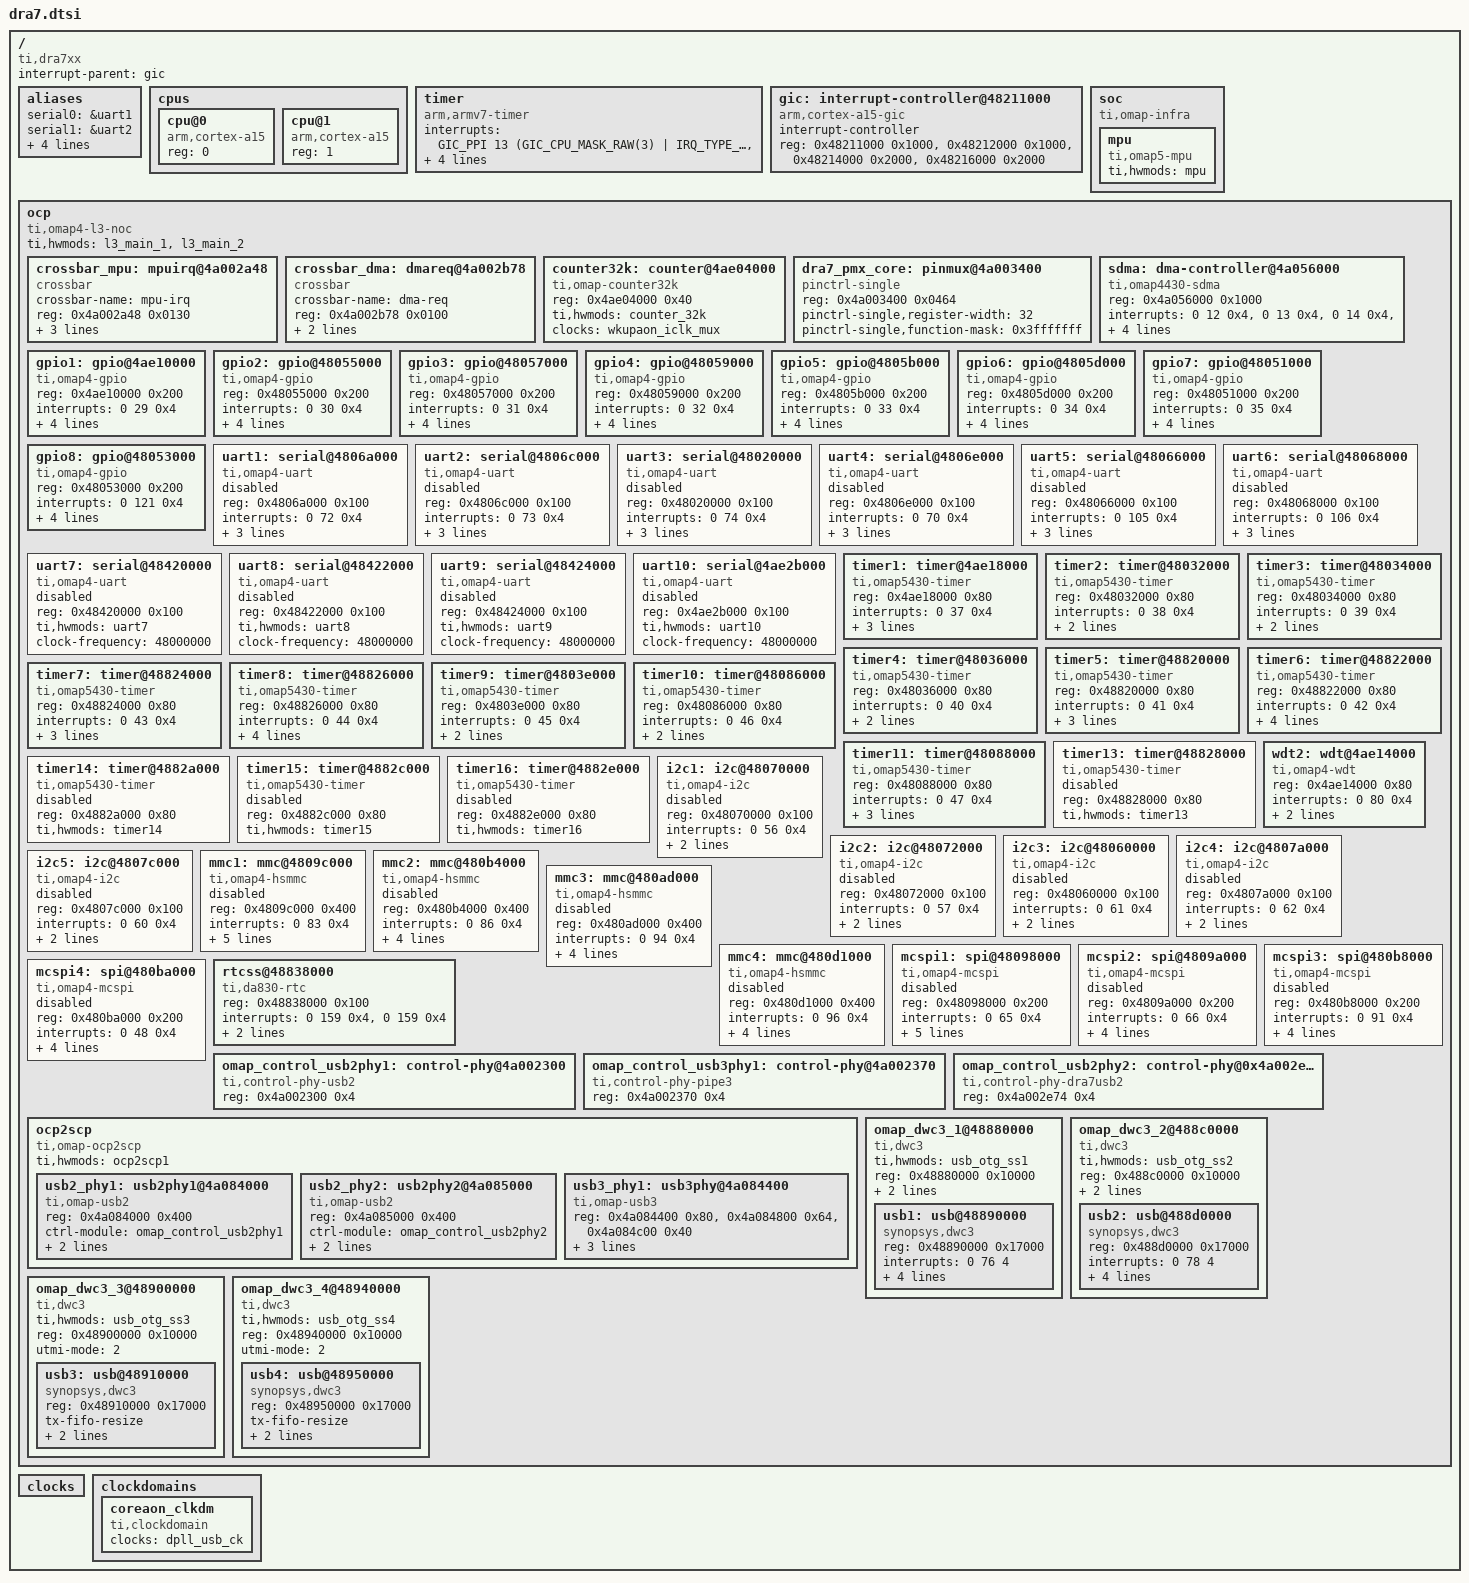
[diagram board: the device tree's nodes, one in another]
/*
 * Copyright (C) 2013 Texas Instruments Incorporated - http://www.ti.com/
 *
 * This program is free software; you can redistribute it and/or modify
 * it under the terms of the GNU General Public License version 2 as
 * published by the Free Software Foundation.
 * Based on "omap4.dtsi"
 */

#include <dt-bindings/interrupt-controller/arm-gic.h>

#include "skeleton.dtsi"

/ {
	compatible = "ti,dra7xx";
	interrupt-parent = <&gic>;

	aliases {
		serial0 = &uart1;
		serial1 = &uart2;
		serial2 = &uart3;
		serial3 = &uart4;
		serial4 = &uart5;
		serial5 = &uart6;
	};

	cpus {
		#address-cells = <1>;
		#size-cells = <0>;

		cpu@0 {
			device_type = "cpu";
			compatible = "arm,cortex-a15";
			reg = <0>;
		};
		cpu@1 {
			device_type = "cpu";
			compatible = "arm,cortex-a15";
			reg = <1>;
		};
	};

	timer {
		compatible = "arm,armv7-timer";
		/* PPI secure/nonsecure IRQ */
		interrupts = <GIC_PPI 13 (GIC_CPU_MASK_RAW(3) | IRQ_TYPE_LEVEL_LOW)>,
			     <GIC_PPI 14 (GIC_CPU_MASK_RAW(3) | IRQ_TYPE_LEVEL_LOW)>,
			     <GIC_PPI 11 (GIC_CPU_MASK_RAW(3) | IRQ_TYPE_LEVEL_LOW)>,
			     <GIC_PPI 10 (GIC_CPU_MASK_RAW(3) | IRQ_TYPE_LEVEL_LOW)>;
		clock-frequency = <6144000>;
	};

	gic: interrupt-controller@48211000 {
		compatible = "arm,cortex-a15-gic";
		interrupt-controller;
		#interrupt-cells = <3>;
		reg = <0x48211000 0x1000>,
		      <0x48212000 0x1000>,
		      <0x48214000 0x2000>,
		      <0x48216000 0x2000>;
	};

	/*
	 * The soc node represents the soc top level view. It is uses for IPs
	 * that are not memory mapped in the MPU view or for the MPU itself.
	 */
	soc {
		compatible = "ti,omap-infra";
		mpu {
			compatible = "ti,omap5-mpu";
			ti,hwmods = "mpu";
		};
	};

	/*
	 * XXX: Use a flat representation of the SOC interconnect.
	 * The real OMAP interconnect network is quite complex.
	 * Since that will not bring real advantage to represent that in DT for
	 * the moment, just use a fake OCP bus entry to represent the whole bus
	 * hierarchy.
	 */
	ocp {
		compatible = "ti,omap4-l3-noc", "simple-bus";
		#address-cells = <1>;
		#size-cells = <1>;
		ranges;
		ti,hwmods = "l3_main_1", "l3_main_2";

		crossbar_mpu: mpuirq@4a002a48 {
			compatible = "crossbar";
			crossbar-name = "mpu-irq";
			reg = <0x4a002a48 0x0130>;
			reg-width = <16>;
			crossbar-lines = "mpu-irq", "rtc-ss-alarm", <0x9f 0xd9 0x12e>,
					 "mpu-irq", "mcasp3-arevt", <0x9e 0x96 0x12c>,
					 "mpu-irq", "mcasp3-axevt", <0x9d 0x97 0x12a>;
		};

		crossbar_dma: dmareq@4a002b78 {
			compatible = "crossbar";
			crossbar-name = "dma-req";
			reg = <0x4a002b78 0x0100>;
			reg-width = <16>;
			crossbar-lines = "dma-req", "mcasp3-rx", <0x7e 0x84 0xfc>,
					 "dma-req", "mcasp3-tx", <0x7d 0x85 0xfa>;
		};

		counter32k: counter@4ae04000 {
			compatible = "ti,omap-counter32k";
			reg = <0x4ae04000 0x40>;
			ti,hwmods = "counter_32k";
			clocks = <&wkupaon_iclk_mux>;
			clock-names = "fck";
		};

		dra7_pmx_core: pinmux@4a003400 {
			compatible = "pinctrl-single";
			reg = <0x4a003400 0x0464>;
			#address-cells = <1>;
			#size-cells = <0>;
			pinctrl-single,register-width = <32>;
			pinctrl-single,function-mask = <0x3fffffff>;
		};

		sdma: dma-controller@4a056000 {
			compatible = "ti,omap4430-sdma";
			reg = <0x4a056000 0x1000>;
			interrupts = <0 12 0x4>,
				     <0 13 0x4>,
				     <0 14 0x4>,
				     <0 15 0x4>;
			#dma-cells = <1>;
			#dma-channels = <32>;
			#dma-requests = <127>;
			clocks = <&l3_iclk_div>;
			clock-names = "fck";
		};

		gpio1: gpio@4ae10000 {
			compatible = "ti,omap4-gpio";
			reg = <0x4ae10000 0x200>;
			interrupts = <0 29 0x4>;
			ti,hwmods = "gpio1";
			clocks = <&wkupaon_iclk_mux>, <&gpio1_dbclk>;
			clock-names = "fck", "dbclk";
			gpio-controller;
			#gpio-cells = <2>;
			interrupt-controller;
			#interrupt-cells = <1>;
		};

		gpio2: gpio@48055000 {
			compatible = "ti,omap4-gpio";
			reg = <0x48055000 0x200>;
			interrupts = <0 30 0x4>;
			ti,hwmods = "gpio2";
			clocks = <&l3_iclk_div>, <&gpio2_dbclk>;
			clock-names = "fck", "dbclk";
			gpio-controller;
			#gpio-cells = <2>;
			interrupt-controller;
			#interrupt-cells = <1>;
		};

		gpio3: gpio@48057000 {
			compatible = "ti,omap4-gpio";
			reg = <0x48057000 0x200>;
			interrupts = <0 31 0x4>;
			ti,hwmods = "gpio3";
			clocks = <&l3_iclk_div>, <&gpio3_dbclk>;
			clock-names = "fck", "dbclk";
			gpio-controller;
			#gpio-cells = <2>;
			interrupt-controller;
			#interrupt-cells = <1>;
		};

		gpio4: gpio@48059000 {
			compatible = "ti,omap4-gpio";
			reg = <0x48059000 0x200>;
			interrupts = <0 32 0x4>;
			ti,hwmods = "gpio4";
			clocks = <&l3_iclk_div>, <&gpio4_dbclk>;
			clock-names = "fck", "dbclk";
			gpio-controller;
			#gpio-cells = <2>;
			interrupt-controller;
			#interrupt-cells = <1>;
		};

		gpio5: gpio@4805b000 {
			compatible = "ti,omap4-gpio";
			reg = <0x4805b000 0x200>;
			interrupts = <0 33 0x4>;
			ti,hwmods = "gpio5";
			clocks = <&l3_iclk_div>, <&gpio5_dbclk>;
			clock-names = "fck", "dbclk";
			gpio-controller;
			#gpio-cells = <2>;
			interrupt-controller;
			#interrupt-cells = <1>;
		};

		gpio6: gpio@4805d000 {
			compatible = "ti,omap4-gpio";
			reg = <0x4805d000 0x200>;
			interrupts = <0 34 0x4>;
			ti,hwmods = "gpio6";
			clocks = <&l3_iclk_div>, <&gpio6_dbclk>;
			clock-names = "fck", "dbclk";
			gpio-controller;
			#gpio-cells = <2>;
			interrupt-controller;
			#interrupt-cells = <1>;
		};

		gpio7: gpio@48051000 {
			compatible = "ti,omap4-gpio";
			reg = <0x48051000 0x200>;
			interrupts = <0 35 0x4>;
			ti,hwmods = "gpio7";
			clocks = <&l3_iclk_div>, <&gpio7_dbclk>;
			clock-names = "fck", "dbclk";
			gpio-controller;
			#gpio-cells = <2>;
			interrupt-controller;
			#interrupt-cells = <1>;
		};

		gpio8: gpio@48053000 {
			compatible = "ti,omap4-gpio";
			reg = <0x48053000 0x200>;
			interrupts = <0 121 0x4>;
			ti,hwmods = "gpio8";
			clocks = <&l3_iclk_div>, <&gpio8_dbclk>;
			clock-names = "fck", "dbclk";
			gpio-controller;
			#gpio-cells = <2>;
			interrupt-controller;
			#interrupt-cells = <1>;
		};

		uart1: serial@4806a000 {
			compatible = "ti,omap4-uart";
			reg = <0x4806a000 0x100>;
			interrupts = <0 72 0x4>;
			ti,hwmods = "uart1";
			clocks = <&uart1_gfclk_mux>;
			clock-names = "fck";
			clock-frequency = <48000000>;
			status = "disabled";
		};

		uart2: serial@4806c000 {
			compatible = "ti,omap4-uart";
			reg = <0x4806c000 0x100>;
			interrupts = <0 73 0x4>;
			ti,hwmods = "uart2";
			clocks = <&uart2_gfclk_mux>;
			clock-names = "fck";
			clock-frequency = <48000000>;
			status = "disabled";
		};

		uart3: serial@48020000 {
			compatible = "ti,omap4-uart";
			reg = <0x48020000 0x100>;
			interrupts = <0 74 0x4>;
			ti,hwmods = "uart3";
			clocks = <&uart3_gfclk_mux>;
			clock-names = "fck";
			clock-frequency = <48000000>;
			status = "disabled";
		};

		uart4: serial@4806e000 {
			compatible = "ti,omap4-uart";
			reg = <0x4806e000 0x100>;
			interrupts = <0 70 0x4>;
			ti,hwmods = "uart4";
			clocks = <&uart4_gfclk_mux>;
			clock-names = "fck";
			clock-frequency = <48000000>;
                        status = "disabled";
		};

		uart5: serial@48066000 {
			compatible = "ti,omap4-uart";
			reg = <0x48066000 0x100>;
			interrupts = <0 105 0x4>;
			ti,hwmods = "uart5";
			clocks = <&uart5_gfclk_mux>;
			clock-names = "fck";
			clock-frequency = <48000000>;
			status = "disabled";
		};

		uart6: serial@48068000 {
			compatible = "ti,omap4-uart";
			reg = <0x48068000 0x100>;
			interrupts = <0 106 0x4>;
			ti,hwmods = "uart6";
			clocks = <&uart6_gfclk_mux>;
			clock-names = "fck";
			clock-frequency = <48000000>;
			status = "disabled";
		};

		uart7: serial@48420000 {
			compatible = "ti,omap4-uart";
			reg = <0x48420000 0x100>;
			ti,hwmods = "uart7";
			clock-frequency = <48000000>;
			status = "disabled";
		};

		uart8: serial@48422000 {
			compatible = "ti,omap4-uart";
			reg = <0x48422000 0x100>;
			ti,hwmods = "uart8";
			clock-frequency = <48000000>;
			status = "disabled";
		};

		uart9: serial@48424000 {
			compatible = "ti,omap4-uart";
			reg = <0x48424000 0x100>;
			ti,hwmods = "uart9";
			clock-frequency = <48000000>;
			status = "disabled";
		};

		uart10: serial@4ae2b000 {
			compatible = "ti,omap4-uart";
			reg = <0x4ae2b000 0x100>;
			ti,hwmods = "uart10";
			clock-frequency = <48000000>;
			status = "disabled";
		};

		timer1: timer@4ae18000 {
			compatible = "ti,omap5430-timer";
			reg = <0x4ae18000 0x80>;
			interrupts = <0 37 0x4>;
			ti,hwmods = "timer1";
			clocks = <&timer1_gfclk_mux>;
			clock-names = "fck";
			ti,timer-alwon;
		};

		timer2: timer@48032000 {
			compatible = "ti,omap5430-timer";
			reg = <0x48032000 0x80>;
			interrupts = <0 38 0x4>;
			ti,hwmods = "timer2";
			clocks = <&timer2_gfclk_mux>;
			clock-names = "fck";
		};

		timer3: timer@48034000 {
			compatible = "ti,omap5430-timer";
			reg = <0x48034000 0x80>;
			interrupts = <0 39 0x4>;
			ti,hwmods = "timer3";
			clocks = <&timer3_gfclk_mux>;
			clock-names = "fck";
		};

		timer4: timer@48036000 {
			compatible = "ti,omap5430-timer";
			reg = <0x48036000 0x80>;
			interrupts = <0 40 0x4>;
			ti,hwmods = "timer4";
			clocks = <&timer4_gfclk_mux>;
			clock-names = "fck";
		};

		timer5: timer@48820000 {
			compatible = "ti,omap5430-timer";
			reg = <0x48820000 0x80>;
			interrupts = <0 41 0x4>;
			ti,hwmods = "timer5";
			clocks = <&timer5_gfclk_mux>;
			clock-names = "fck";
			ti,timer-dsp;
		};

		timer6: timer@48822000 {
			compatible = "ti,omap5430-timer";
			reg = <0x48822000 0x80>;
			interrupts = <0 42 0x4>;
			ti,hwmods = "timer6";
			clocks = <&timer6_gfclk_mux>;
			clock-names = "fck";
			ti,timer-dsp;
			ti,timer-pwm;
		};

		timer7: timer@48824000 {
			compatible = "ti,omap5430-timer";
			reg = <0x48824000 0x80>;
			interrupts = <0 43 0x4>;
			ti,hwmods = "timer7";
			clocks = <&timer7_gfclk_mux>;
			clock-names = "fck";
			ti,timer-dsp;
		};

		timer8: timer@48826000 {
			compatible = "ti,omap5430-timer";
			reg = <0x48826000 0x80>;
			interrupts = <0 44 0x4>;
			ti,hwmods = "timer8";
			clocks = <&timer8_gfclk_mux>;
			clock-names = "fck";
			ti,timer-dsp;
			ti,timer-pwm;
		};

		timer9: timer@4803e000 {
			compatible = "ti,omap5430-timer";
			reg = <0x4803e000 0x80>;
			interrupts = <0 45 0x4>;
			ti,hwmods = "timer9";
			clocks = <&timer9_gfclk_mux>;
			clock-names = "fck";
		};

		timer10: timer@48086000 {
			compatible = "ti,omap5430-timer";
			reg = <0x48086000 0x80>;
			interrupts = <0 46 0x4>;
			ti,hwmods = "timer10";
			clocks = <&timer10_gfclk_mux>;
			clock-names = "fck";
		};

		timer11: timer@48088000 {
			compatible = "ti,omap5430-timer";
			reg = <0x48088000 0x80>;
			interrupts = <0 47 0x4>;
			ti,hwmods = "timer11";
			clocks = <&timer11_gfclk_mux>;
			clock-names = "fck";
			ti,timer-pwm;
		};

		timer13: timer@48828000 {
			compatible = "ti,omap5430-timer";
			reg = <0x48828000 0x80>;
			ti,hwmods = "timer13";
			status = "disabled";
		};

		timer14: timer@4882a000 {
			compatible = "ti,omap5430-timer";
			reg = <0x4882a000 0x80>;
			ti,hwmods = "timer14";
			status = "disabled";
		};

		timer15: timer@4882c000 {
			compatible = "ti,omap5430-timer";
			reg = <0x4882c000 0x80>;
			ti,hwmods = "timer15";
			status = "disabled";
		};

		timer16: timer@4882e000 {
			compatible = "ti,omap5430-timer";
			reg = <0x4882e000 0x80>;
			ti,hwmods = "timer16";
			status = "disabled";
		};

		wdt2: wdt@4ae14000 {
			compatible = "ti,omap4-wdt";
			reg = <0x4ae14000 0x80>;
			interrupts = <0 80 0x4>;
			ti,hwmods = "wd_timer2";
			clocks = <&sys_32k_ck>;
			clock-names = "fck";
		};

		i2c1: i2c@48070000 {
			compatible = "ti,omap4-i2c";
			reg = <0x48070000 0x100>;
			interrupts = <0 56 0x4>;
			#address-cells = <1>;
			#size-cells = <0>;
			ti,hwmods = "i2c1";
			clocks = <&func_96m_fclk>;
			clock-names = "fck";
			status = "disabled";
		};

		i2c2: i2c@48072000 {
			compatible = "ti,omap4-i2c";
			reg = <0x48072000 0x100>;
			interrupts = <0 57 0x4>;
			#address-cells = <1>;
			#size-cells = <0>;
			ti,hwmods = "i2c2";
			clocks = <&func_96m_fclk>;
			clock-names = "fck";
			status = "disabled";
		};

		i2c3: i2c@48060000 {
			compatible = "ti,omap4-i2c";
			reg = <0x48060000 0x100>;
			interrupts = <0 61 0x4>;
			#address-cells = <1>;
			#size-cells = <0>;
			ti,hwmods = "i2c3";
			clocks = <&func_96m_fclk>;
			clock-names = "fck";
			status = "disabled";
		};

		i2c4: i2c@4807a000 {
			compatible = "ti,omap4-i2c";
			reg = <0x4807a000 0x100>;
			interrupts = <0 62 0x4>;
			#address-cells = <1>;
			#size-cells = <0>;
			ti,hwmods = "i2c4";
			clocks = <&func_96m_fclk>;
			clock-names = "fck";
			status = "disabled";
		};

		i2c5: i2c@4807c000 {
			compatible = "ti,omap4-i2c";
			reg = <0x4807c000 0x100>;
			interrupts = <0 60 0x4>;
			#address-cells = <1>;
			#size-cells = <0>;
			ti,hwmods = "i2c5";
			clocks = <&func_96m_fclk>;
			clock-names = "fck";
			status = "disabled";
		};

		mmc1: mmc@4809c000 {
			compatible = "ti,omap4-hsmmc";
			reg = <0x4809c000 0x400>;
			interrupts = <0 83 0x4>;
			ti,hwmods = "mmc1";
			clocks = <&mmc1_fclk_div>, <&mmc1_clk32k>;
			clock-names = "fck", "clk32k";
			ti,dual-volt;
			ti,needs-special-reset;
			dmas = <&sdma 61>, <&sdma 62>;
			dma-names = "tx", "rx";
			status = "disabled";
		};

		mmc2: mmc@480b4000 {
			compatible = "ti,omap4-hsmmc";
			reg = <0x480b4000 0x400>;
			interrupts = <0 86 0x4>;
			ti,hwmods = "mmc2";
			clocks = <&mmc2_fclk_div>, <&mmc2_clk32k>;
			clock-names = "fck", "clk32k";
			ti,needs-special-reset;
			dmas = <&sdma 47>, <&sdma 48>;
			dma-names = "tx", "rx";
			status = "disabled";
		};

		mmc3: mmc@480ad000 {
			compatible = "ti,omap4-hsmmc";
			reg = <0x480ad000 0x400>;
			interrupts = <0 94 0x4>;
			ti,hwmods = "mmc3";
			clocks = <&mmc3_gfclk_div>, <&mmc3_clk32k>;
			clock-names = "fck", "clk32k";
			ti,needs-special-reset;
			dmas = <&sdma 77>, <&sdma 78>;
			dma-names = "tx", "rx";
			status = "disabled";
		};

		mmc4: mmc@480d1000 {
			compatible = "ti,omap4-hsmmc";
			reg = <0x480d1000 0x400>;
			interrupts = <0 96 0x4>;
			ti,hwmods = "mmc4";
			clocks = <&mmc4_gfclk_div>, <&mmc4_clk32k>;
			clock-names = "fck", "clk32k";
			ti,needs-special-reset;
			dmas = <&sdma 57>, <&sdma 58>;
			dma-names = "tx", "rx";
			status = "disabled";
		};

		mcspi1: spi@48098000 {
			compatible = "ti,omap4-mcspi";
			reg = <0x48098000 0x200>;
			interrupts = <0 65 0x4>;
			#address-cells = <1>;
			#size-cells = <0>;
			ti,hwmods = "mcspi1";
			clocks = <&func_48m_fclk>;
			clock-names = "fck";
			ti,spi-num-cs = <4>;
			dmas = <&sdma 35>,
			       <&sdma 36>,
			       <&sdma 37>,
			       <&sdma 38>,
			       <&sdma 39>,
			       <&sdma 40>,
			       <&sdma 41>,
			       <&sdma 42>;
			dma-names = "tx0", "rx0", "tx1", "rx1",
				    "tx2", "rx2", "tx3", "rx3";
			status = "disabled";
		};

		mcspi2: spi@4809a000 {
			compatible = "ti,omap4-mcspi";
			reg = <0x4809a000 0x200>;
			interrupts = <0 66 0x4>;
			#address-cells = <1>;
			#size-cells = <0>;
			ti,hwmods = "mcspi2";
			clocks = <&func_48m_fclk>;
			clock-names = "fck";
			ti,spi-num-cs = <2>;
			dmas = <&sdma 43>,
			       <&sdma 44>,
			       <&sdma 45>,
			       <&sdma 46>;
			dma-names = "tx0", "rx0", "tx1", "rx1";
			status = "disabled";
		};

		mcspi3: spi@480b8000 {
			compatible = "ti,omap4-mcspi";
			reg = <0x480b8000 0x200>;
			interrupts = <0 91 0x4>;
			#address-cells = <1>;
			#size-cells = <0>;
			ti,hwmods = "mcspi3";
			clocks = <&func_48m_fclk>;
			clock-names = "fck";
			ti,spi-num-cs = <2>;
			dmas = <&sdma 15>, <&sdma 16>;
			dma-names = "tx0", "rx0";
			status = "disabled";
		};

		mcspi4: spi@480ba000 {
			compatible = "ti,omap4-mcspi";
			reg = <0x480ba000 0x200>;
			interrupts = <0 48 0x4>;
			#address-cells = <1>;
			#size-cells = <0>;
			ti,hwmods = "mcspi4";
			clocks = <&func_48m_fclk>;
			clock-names = "fck";
			ti,spi-num-cs = <1>;
			dmas = <&sdma 70>, <&sdma 71>;
			dma-names = "tx0", "rx0";
			status = "disabled";
		};

		rtcss@48838000 {
			compatible = "ti,da830-rtc";
			reg = <0x48838000 0x100>;
			interrupts = <0 159 0x4>,
				     <0 159 0x4>;
			ti,hwmods = "rtcss";
			clocks = <&sys_32k_ck>;
			clock-names = "fck";
		};

		omap_control_usb2phy1: control-phy@4a002300 {
			compatible = "ti,control-phy-usb2";
			reg = <0x4a002300 0x4>;
			reg-names = "power";
		};

		omap_control_usb3phy1: control-phy@4a002370 {
			compatible = "ti,control-phy-pipe3";
			reg = <0x4a002370 0x4>;
			reg-names = "power";
		};

		omap_control_usb2phy2: control-phy@0x4a002e74 {
			compatible = "ti,control-phy-dra7usb2";
			reg = <0x4a002e74 0x4>;
			reg-names = "power";
		};

		ocp2scp {
			compatible = "ti,omap-ocp2scp";
			#address-cells = <1>;
			#size-cells = <1>;
			ranges;
			ti,hwmods = "ocp2scp1";

			usb2_phy1: usb2phy1@4a084000 {
				compatible = "ti,omap-usb2";
				reg = <0x4a084000 0x400>;
				ctrl-module = <&omap_control_usb2phy1>;
				clocks = <&usb_phy1_always_on_clk32k>,
					 <&usb_otg_ss1_refclk960m>;
				clock-names =	"wkupclk",
						"refclk";
			};

			usb2_phy2: usb2phy2@4a085000 {
				compatible = "ti,omap-usb2";
				reg = <0x4a085000 0x400>;
				ctrl-module = <&omap_control_usb2phy2>;
				clocks = <&usb_phy2_always_on_clk32k>,
					 <&usb_otg_ss2_refclk960m>;
				clock-names =	"wkupclk",
						"refclk";
			};

			usb3_phy1: usb3phy@4a084400 {
				compatible = "ti,omap-usb3";
				reg = <0x4a084400 0x80>,
				      <0x4a084800 0x64>,
				      <0x4a084c00 0x40>;
				reg-names = "phy_rx", "phy_tx", "pll_ctrl";
				ctrl-module = <&omap_control_usb3phy1>;
				clocks = <&usb_phy1_always_on_clk32k>,
					 <&usb_otg_ss1_refclk960m>,
					 <&dpll_core_h13x2_ck>;
				clock-names =	"wkupclk",
						"refclk",
						"refclk2";
			};
		};

		omap_dwc3_1@48880000 {
			compatible = "ti,dwc3";
			ti,hwmods = "usb_otg_ss1";
			reg = <0x48880000 0x10000>;
			interrupts = <0 77 4>;
			#address-cells = <1>;
			#size-cells = <1>;
			utmi-mode = <2>;
			ranges;
			usb1: usb@48890000 {
				compatible = "synopsys,dwc3";
				reg = <0x48890000 0x17000>;
				interrupts = <0 76 4>;
				usb-phy = <&usb2_phy1>, <&usb3_phy1>;
				tx-fifo-resize;
				maximum-speed = "super-speed";
				dr_mode = "otg";
			};
		};

		omap_dwc3_2@488c0000 {
			compatible = "ti,dwc3";
			ti,hwmods = "usb_otg_ss2";
			reg = <0x488c0000 0x10000>;
			interrupts = <0 92 4>;
			#address-cells = <1>;
			#size-cells = <1>;
			utmi-mode = <2>;
			ranges;
			usb2: usb@488d0000 {
				compatible = "synopsys,dwc3";
				reg = <0x488d0000 0x17000>;
				interrupts = <0 78 4>;
				usb-phy = <&usb2_phy2>;
				tx-fifo-resize;
				maximum-speed = "high-speed";
				dr_mode = "otg";
			};
		};

		/* IRQ for DWC3_3 and DWC3_4 need IRQ crossbar */
		omap_dwc3_3@48900000 {
			compatible = "ti,dwc3";
			ti,hwmods = "usb_otg_ss3";
			reg = <0x48900000 0x10000>;
		/*	interrupts = <0 TBD 4>; */
			#address-cells = <1>;
			#size-cells = <1>;
			utmi-mode = <2>;
			ranges;
			usb3: usb@48910000 {
				compatible = "synopsys,dwc3";
				reg = <0x48910000 0x17000>;
		/*		interrupts = <0 93 4>; */
				tx-fifo-resize;
				maximum-speed = "high-speed";
				dr_mode = "otg";
			};
		};

		omap_dwc3_4@48940000 {
			compatible = "ti,dwc3";
			ti,hwmods = "usb_otg_ss4";
			reg = <0x48940000 0x10000>;
		/*	interrupts = <0 TBD 4>; */
			#address-cells = <1>;
			#size-cells = <1>;
			utmi-mode = <2>;
			ranges;
			usb4: usb@48950000 {
				compatible = "synopsys,dwc3";
				reg = <0x48950000 0x17000>;
		/*		interrupts = <0 TBD 4>; */
				tx-fifo-resize;
				maximum-speed = "high-speed";
				dr_mode = "otg";
			};
		};

	};

	clocks {
		#address-cells = <1>;
		#size-cells = <1>;
		ranges;
		/include/ "dra7xx-clocks.dtsi"
	};

	clockdomains {
		coreaon_clkdm: coreaon_clkdm {
			compatible = "ti,clockdomain";
			clocks = <&dpll_usb_ck>;
		};
	};
};
